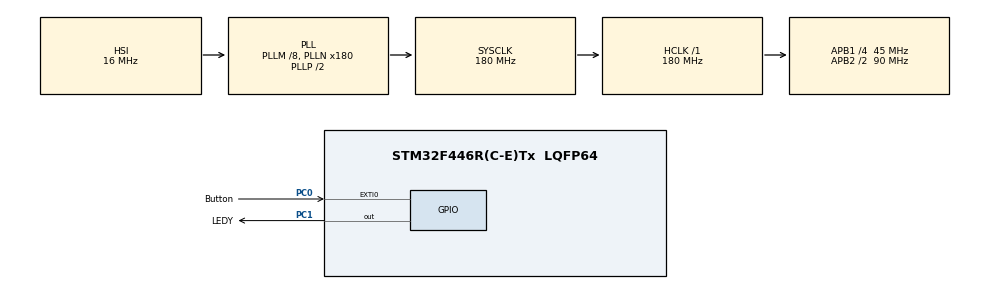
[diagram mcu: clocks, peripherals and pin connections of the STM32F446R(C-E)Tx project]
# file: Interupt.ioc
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Mcu.Family=STM32F4
Mcu.Name=STM32F446R(C-E)Tx
Mcu.Package=LQFP64
NVIC.PriorityGroup=NVIC_PRIORITYGROUP_4
PA13.Mode=Serial_Wire
PA13.Signal=SYS_JTMS-SWDIO
PA14.Mode=Serial_Wire
PA14.Signal=SYS_JTCK-SWCLK
PC0.GPIO_Label=Button
PC0.GPIO_PuPd=GPIO_PULLUP
PC0.Signal=GPXTI0
PC1.GPIO_Label=LEDY
PC1.Signal=GPIO_Output
ProjectManager.HeapSize=0x200
ProjectManager.StackSize=0x400
ProjectManager.TargetToolchain=STM32CubeIDE
RCC.AHBFreq_Value=180000000
RCC.APB1CLKDivider=RCC_HCLK_DIV4
RCC.APB1Freq_Value=45000000
RCC.APB1TimFreq_Value=90000000
RCC.APB2CLKDivider=RCC_HCLK_DIV2
RCC.APB2Freq_Value=90000000
RCC.APB2TimFreq_Value=180000000
RCC.CortexFreq_Value=180000000
RCC.HCLKFreq_Value=180000000
RCC.PLLM=8
RCC.PLLN=180
RCC.SYSCLKFreq_VALUE=180000000
RCC.SYSCLKSource=RCC_SYSCLKSOURCE_PLLCLK
RCC.USBFreq_Value=180000000
RCC.VCOOutputFreq_Value=360000000
board=custom

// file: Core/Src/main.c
/* USER CODE BEGIN Header */
/**
  ******************************************************************************
  * @file           : main.c
  * @brief          : Main program body
  ******************************************************************************
  * @attention
  *
  * Copyright (c) 2026 STMicroelectronics.
  * All rights reserved.
  *
  * This software is licensed under terms that can be found in the LICENSE file
  * in the root directory of this software component.
  * If no LICENSE file comes with this software, it is provided AS-IS.
  *
  ******************************************************************************
  */
/* USER CODE END Header */
#include "main.h"

/* USER CODE BEGIN Includes */
#include "button.h"
#include "led.h"
#include "exti_dispatcher.h"
/* USER CODE END Includes */

void SystemClock_Config(void);
static void MX_GPIO_Init(void);

int main(void)
{

  /* MCU Configuration--------------------------------------------------------*/

  /* Reset of all peripherals, Initializes the Flash interface and the Systick. */
  HAL_Init();

  /* Configure the system clock */
  SystemClock_Config();

  /* Initialize all configured peripherals */
  MX_GPIO_Init();
  /* USER CODE BEGIN 2 */

  EXTI_Dispatcher_Register(Button_Pin, Button_EXTI_Callback);
  /* USER CODE END 2 */

  /* Infinite loop */
  while (1)
  {

    /* USER CODE BEGIN 3 */
    Button_Handle();
    LED_Handle();
  }
  /* USER CODE END 3 */
}

void SystemClock_Config(void)
{
  RCC_OscInitTypeDef RCC_OscInitStruct = {0};
  RCC_ClkInitTypeDef RCC_ClkInitStruct = {0};

  /** Configure the main internal regulator output voltage
  */
  __HAL_RCC_PWR_CLK_ENABLE();
  __HAL_PWR_VOLTAGESCALING_CONFIG(PWR_REGULATOR_VOLTAGE_SCALE1);

  /** Initializes the RCC Oscillators according to the specified parameters
  * in the RCC_OscInitTypeDef structure.
  */
  RCC_OscInitStruct.OscillatorType = RCC_OSCILLATORTYPE_HSI;
  RCC_OscInitStruct.HSIState = RCC_HSI_ON;
  RCC_OscInitStruct.HSICalibrationValue = RCC_HSICALIBRATION_DEFAULT;
  RCC_OscInitStruct.PLL.PLLState = RCC_PLL_ON;
  RCC_OscInitStruct.PLL.PLLSource = RCC_PLLSOURCE_HSI;
  RCC_OscInitStruct.PLL.PLLM = 8;
  RCC_OscInitStruct.PLL.PLLN = 180;
  RCC_OscInitStruct.PLL.PLLP = RCC_PLLP_DIV2;
  RCC_OscInitStruct.PLL.PLLQ = 2;
  RCC_OscInitStruct.PLL.PLLR = 2;
  if (HAL_RCC_OscConfig(&RCC_OscInitStruct) != HAL_OK)
  {
    Error_Handler();
  }

  /** Activate the Over-Drive mode
  */
  if (HAL_PWREx_EnableOverDrive() != HAL_OK)
  {
    Error_Handler();
  }

  /** Initializes the CPU, AHB and APB buses clocks
  */
  RCC_ClkInitStruct.ClockType = RCC_CLOCKTYPE_HCLK|RCC_CLOCKTYPE_SYSCLK
                              |RCC_CLOCKTYPE_PCLK1|RCC_CLOCKTYPE_PCLK2;
  RCC_ClkInitStruct.SYSCLKSource = RCC_SYSCLKSOURCE_PLLCLK;
  RCC_ClkInitStruct.AHBCLKDivider = RCC_SYSCLK_DIV1;
  RCC_ClkInitStruct.APB1CLKDivider = RCC_HCLK_DIV4;
  RCC_ClkInitStruct.APB2CLKDivider = RCC_HCLK_DIV2;

  if (HAL_RCC_ClockConfig(&RCC_ClkInitStruct, FLASH_LATENCY_5) != HAL_OK)
  {
    Error_Handler();
  }
}

static void MX_GPIO_Init(void)
{
  GPIO_InitTypeDef GPIO_InitStruct = {0};

  /* GPIO Ports Clock Enable */
  __HAL_RCC_GPIOC_CLK_ENABLE();

  /*Configure GPIO pin Output Level : LEDY (PC1) */
  HAL_GPIO_WritePin(LEDY_GPIO_Port, LEDY_Pin, GPIO_PIN_RESET);

  /*Configure GPIO pin : LEDY_Pin (PC1) - output, drives the LED */
  GPIO_InitStruct.Pin = LEDY_Pin;
  GPIO_InitStruct.Mode = GPIO_MODE_OUTPUT_PP;
  GPIO_InitStruct.Pull = GPIO_NOPULL;
  GPIO_InitStruct.Speed = GPIO_SPEED_FREQ_LOW;
  HAL_GPIO_Init(LEDY_GPIO_Port, &GPIO_InitStruct);

  /*Configure GPIO pin : Button_Pin (PC0) - EXTI both edges (press = falling, release = rising) */
  GPIO_InitStruct.Pin = Button_Pin;
  GPIO_InitStruct.Mode = GPIO_MODE_IT_RISING_FALLING;
  GPIO_InitStruct.Pull = GPIO_PULLUP;
  HAL_GPIO_Init(Button_GPIO_Port, &GPIO_InitStruct);

  /* USER CODE BEGIN MX_GPIO_Init_2 */
  // Enable the EXTI0 interrupt in the NVIC. Placed here (instead of ticking
  // the NVIC tab in CubeMX) so it survives code regeneration from the .ioc.
  HAL_NVIC_SetPriority(EXTI0_IRQn, 2, 0);
  HAL_NVIC_EnableIRQ(EXTI0_IRQn);
  /* USER CODE END MX_GPIO_Init_2 */
}

/* USER CODE BEGIN 4 */
// HAL declares this function as "weak" in stm32f4xx_hal_gpio.c. Defining it
// here makes the linker use our version instead of HAL's empty one. It no
// longer knows anything about Button - it just hands off to the dispatcher,
// which looks up and calls whichever callback was registered for this pin.
void HAL_GPIO_EXTI_Callback(uint16_t GPIO_Pin)
{
  EXTI_Dispatcher_Handle(GPIO_Pin);
}
/* USER CODE END 4 */

void Error_Handler(void)
{
  __disable_irq();
  while (1)
  {
  }
}
